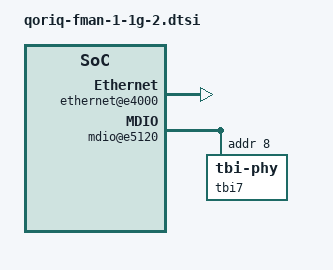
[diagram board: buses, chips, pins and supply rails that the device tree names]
/*
 * QorIQ FMan 1g port #2 device tree stub [ controller @ offset 0x500000 ]
 *
 * Copyright 2011 - 2015 Freescale Semiconductor Inc.
 *
 * Redistribution and use in source and binary forms, with or without
 * modification, are permitted provided that the following conditions are met:
 *     * Redistributions of source code must retain the above copyright
 *	 notice, this list of conditions and the following disclaimer.
 *     * Redistributions in binary form must reproduce the above copyright
 *	 notice, this list of conditions and the following disclaimer in the
 *	 documentation and/or other materials provided with the distribution.
 *     * Neither the name of Freescale Semiconductor nor the
 *	 names of its contributors may be used to endorse or promote products
 *	 derived from this software without specific prior written permission.
 *
 *
 * ALTERNATIVELY, this software may be distributed under the terms of the
 * GNU General Public License ("GPL") as published by the Free Software
 * Foundation, either version 2 of that License or (at your option) any
 * later version.
 *
 * THIS SOFTWARE IS PROVIDED BY Freescale Semiconductor ``AS IS'' AND ANY
 * EXPRESS OR IMPLIED WARRANTIES, INCLUDING, BUT NOT LIMITED TO, THE IMPLIED
 * WARRANTIES OF MERCHANTABILITY AND FITNESS FOR A PARTICULAR PURPOSE ARE
 * DISCLAIMED. IN NO EVENT SHALL Freescale Semiconductor BE LIABLE FOR ANY
 * DIRECT, INDIRECT, INCIDENTAL, SPECIAL, EXEMPLARY, OR CONSEQUENTIAL DAMAGES
 * (INCLUDING, BUT NOT LIMITED TO, PROCUREMENT OF SUBSTITUTE GOODS OR SERVICES;
 * LOSS OF USE, DATA, OR PROFITS; OR BUSINESS INTERRUPTION) HOWEVER CAUSED AND
 * ON ANY THEORY OF LIABILITY, WHETHER IN CONTRACT, STRICT LIABILITY, OR TORT
 * (INCLUDING NEGLIGENCE OR OTHERWISE) ARISING IN ANY WAY OUT OF THE USE OF THIS
 * SOFTWARE, EVEN IF ADVISED OF THE POSSIBILITY OF SUCH DAMAGE.
 */

fman@500000 {
	fman1_rx_0x0a: port@8a000 {
		cell-index = <0xa>;
		compatible = "fsl,fman-v2-port-rx";
		reg = <0x8a000 0x1000>;
	};

	fman1_tx_0x2a: port@aa000 {
		cell-index = <0x2a>;
		compatible = "fsl,fman-v2-port-tx";
		reg = <0xaa000 0x1000>;
	};

	ethernet@e4000 {
		cell-index = <2>;
		compatible = "fsl,fman-dtsec";
		reg = <0xe4000 0x1000>;
		fsl,fman-ports = <&fman1_rx_0x0a &fman1_tx_0x2a>;
		tbi-handle = <&tbi7>;
		ptp-timer = <&ptp_timer1>;
	};

	mdio@e5120 {
		#address-cells = <1>;
		#size-cells = <0>;
		compatible = "fsl,fman-mdio";
		reg = <0xe5120 0xee0>;

		tbi7: tbi-phy@8 {
			reg = <0x8>;
			device_type = "tbi-phy";
		};
	};
};
